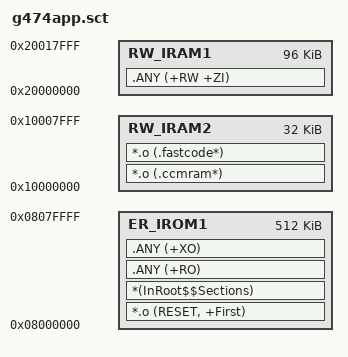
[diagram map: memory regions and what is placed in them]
; *************************************************************
; *** Scatter-Loading Description File generated by uVision ***
; *************************************************************

LR_IROM1 0x08000000 0x00080000  {    ; 512 KB Flash, not split by bank
  ER_IROM1 0x08000000 0x00080000  {  ; load address = execution address
   *.o (RESET, +First)
   *(InRoot$$Sections)
   .ANY (+RO)
   .ANY (+XO)
  }
  RW_IRAM2 0x10000000 0x00008000  {  ; 32 KB CCM SRAM
   *.o (.ccmram*)
   *.o (.fastcode*)
  }
  RW_IRAM1 0x20000000 0x00018000  {  ; 96 KB SRAM
   .ANY (+RW +ZI)
  }
}

